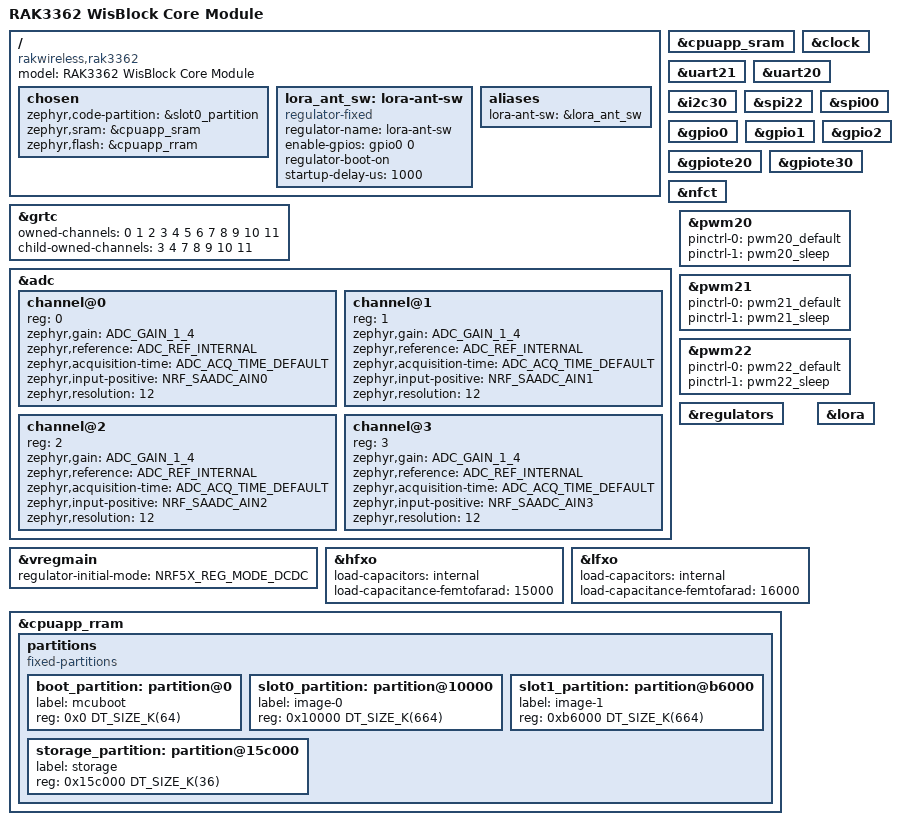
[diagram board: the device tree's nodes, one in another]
/*
 * Copyright (c) 2026 RAK Wireless
 * SPDX-License-Identifier: Apache-2.0
 */

/dts-v1/;
#include <rakwireless/rak3162.dtsi>
#include "rak3362-pinctrl.dtsi"

/ {
	model = "RAK3362 WisBlock Core Module";
	compatible = "rakwireless,rak3362";

	chosen {
		zephyr,code-partition = &slot0_partition;
		zephyr,sram = &cpuapp_sram;
		zephyr,flash = &cpuapp_rram;
	};

	/*
	 * ANT_SW (P0.00) -> R5 (100 ohm) -> RTC66006 VDD (pin 6).
	 * regulator-boot-on keeps the RF switch powered at boot; applications
	 * may call regulator_disable() on lora-ant-sw for low-power operation.
	 */
	lora_ant_sw: lora-ant-sw {
		compatible = "regulator-fixed";
		regulator-name = "lora-ant-sw";
		enable-gpios = <&gpio0 0 GPIO_ACTIVE_HIGH>;
		regulator-boot-on;
		startup-delay-us = <1000>;
	};

	aliases {
		lora-ant-sw = &lora_ant_sw;
	};
};

&cpuapp_sram {
	status = "okay";
};

&grtc {
	owned-channels = <0 1 2 3 4 5 6 7 8 9 10 11>;
	/* Channels 7-11 reserved for Zero Latency IRQs; 3-4 for FLPR */
	child-owned-channels = <3 4 7 8 9 10 11>;
	status = "okay";
};

&clock {
	status = "okay";
};

&uart21 {
	status = "okay";
};

&uart20 {
	status = "okay";
};

&i2c30 {
	status = "okay";
};

&spi22 {
	status = "okay";
};

&spi00 {
	status = "okay";
};

&gpio0 {
	status = "okay";
};

&gpio1 {
	status = "okay";
};

&gpio2 {
	status = "okay";
};

&gpiote20 {
	status = "okay";
};

&gpiote30 {
	status = "okay";
};

&nfct {
	status = "okay";
};

&adc {
	status = "okay";
	#address-cells = <1>;
	#size-cells = <0>;

	channel@0 {
		reg = <0>;
		zephyr,gain = "ADC_GAIN_1_4";
		zephyr,reference = "ADC_REF_INTERNAL";
		zephyr,acquisition-time = <ADC_ACQ_TIME_DEFAULT>;
		zephyr,input-positive = <NRF_SAADC_AIN0>;
		zephyr,resolution = <12>;
	};

	channel@1 {
		reg = <1>;
		zephyr,gain = "ADC_GAIN_1_4";
		zephyr,reference = "ADC_REF_INTERNAL";
		zephyr,acquisition-time = <ADC_ACQ_TIME_DEFAULT>;
		zephyr,input-positive = <NRF_SAADC_AIN1>;
		zephyr,resolution = <12>;
	};

	channel@2 {
		reg = <2>;
		zephyr,gain = "ADC_GAIN_1_4";
		zephyr,reference = "ADC_REF_INTERNAL";
		zephyr,acquisition-time = <ADC_ACQ_TIME_DEFAULT>;
		zephyr,input-positive = <NRF_SAADC_AIN2>;
		zephyr,resolution = <12>;
	};

	channel@3 {
		reg = <3>;
		zephyr,gain = "ADC_GAIN_1_4";
		zephyr,reference = "ADC_REF_INTERNAL";
		zephyr,acquisition-time = <ADC_ACQ_TIME_DEFAULT>;
		zephyr,input-positive = <NRF_SAADC_AIN3>;
		zephyr,resolution = <12>;
	};
};

&pwm20 {
	status = "okay";
	pinctrl-0 = <&pwm20_default>;
	pinctrl-1 = <&pwm20_sleep>;
	pinctrl-names = "default", "sleep";
};

&pwm21 {
	status = "okay";
	pinctrl-0 = <&pwm21_default>;
	pinctrl-1 = <&pwm21_sleep>;
	pinctrl-names = "default", "sleep";
};

&pwm22 {
	status = "okay";
	pinctrl-0 = <&pwm22_default>;
	pinctrl-1 = <&pwm22_sleep>;
	pinctrl-names = "default", "sleep";
};

&regulators {
	status = "okay";
};

&vregmain {
	status = "okay";
	regulator-initial-mode = <NRF5X_REG_MODE_DCDC>;
};

/*
 * HFXO - 32 MHz crystal (optional).
 * Tune load-capacitance-femtofarad to match the crystal (4000-17000 fF,
 * step 250 fF). Remove this node if no crystal is populated.
 */
&hfxo {
	status = "okay";
	load-capacitors = "internal";
	load-capacitance-femtofarad = <15000>;
};

&lfxo {
	load-capacitors = "internal";
	load-capacitance-femtofarad = <16000>;
	status = "okay";
};

&lora {
	status = "okay";
};

&cpuapp_rram {
	partitions {
		compatible = "fixed-partitions";
		#address-cells = <1>;
		#size-cells = <1>;

		boot_partition: partition@0 {
			label = "mcuboot";
			reg = <0x0 DT_SIZE_K(64)>;
		};

		slot0_partition: partition@10000 {
			label = "image-0";
			reg = <0x10000 DT_SIZE_K(664)>;
		};

		slot1_partition: partition@b6000 {
			label = "image-1";
			reg = <0xb6000 DT_SIZE_K(664)>;
		};

		storage_partition: partition@15c000 {
			label = "storage";
			reg = <0x15c000 DT_SIZE_K(36)>;
		};
	};
};

#include "wisblock.dtsi"
